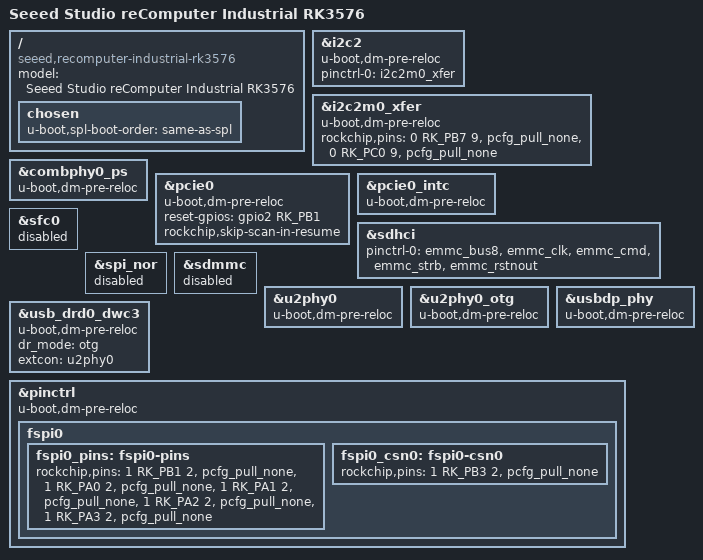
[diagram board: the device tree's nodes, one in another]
// SPDX-License-Identifier: (GPL-2.0+ OR MIT)
/*
 * Copyright (c) 2026 Seeed Studio
 *
 * U-Boot DTS for reComputer Industrial RK3576, eMMC SKU (no TF slot, no SPI
 * flash). Structure follows the hardware-validated devkit DTS (eMMC/fspi0
 * ball-sharing fix); board differences mirror the kernel industrial DTS.
 */

/dts-v1/;
#include "rk3576.dtsi"
#include "rk3576-u-boot.dtsi"

/ {
	model = "Seeed Studio reComputer Industrial RK3576";
	compatible = "seeed,recomputer-industrial-rk3576", "rockchip,rk3576";

	chosen {
		/*
		 * eMMC-only SKU: override the rk3576-u-boot.dtsi default
		 * (sdmmc/spi first). No TF slot, no SPI flash — go straight
		 * to on-board eMMC; "same-as-spl" (= eMMC) as fallback.
		 */
		u-boot,spl-boot-order = &sdhci, "same-as-spl";
	};
};

/*
 * SoM I2C2_M0: EEPROM FT24C32A @0x50 + RTC PCF85063 @0x51.
 * The boot script reads the EEPROM for board-ID DTB selection; the
 * misc.c patch (0011) reads per-port MACs from it (cpuid fallback).
 */
&i2c2 {
	u-boot,dm-pre-reloc;
	status = "okay";
	pinctrl-names = "default";
	pinctrl-0 = <&i2c2m0_xfer>;
};

&i2c2m0_xfer {
	u-boot,dm-pre-reloc;
	rockchip,pins =
		<0 RK_PB7 9 &pcfg_pull_none>,
		<0 RK_PC0 9 &pcfg_pull_none>;
};

/* M.2 Key-M NVMe on PCIE0, PERST GPIO2_B1, 3V3 always-on */
&combphy0_ps {
	u-boot,dm-pre-reloc;
	status = "okay";
};

&pcie0 {
	u-boot,dm-pre-reloc;
	reset-gpios = <&gpio2 RK_PB1 GPIO_ACTIVE_HIGH>;
	rockchip,skip-scan-in-resume;
	status = "okay";
};

&pcie0_intc {
	u-boot,dm-pre-reloc;
};

&sdhci {
	/*
	 * eMMC controller; bus-width/non-removable come from rk3576-u-boot.dtsi.
	 * RK3576 muxes func1=emmc / func2=fspi0 on the same balls
	 * (gpio1 A0-A7, B0-B2). Any fspi0 pinctrl steals the eMMC lines, so
	 * this no-SPI-flash board keeps sfc0/fspi0 disabled and muxes the
	 * pins to emmc explicitly here (same fix as the devkit).
	 */
	status = "okay";
	pinctrl-names = "default";
	pinctrl-0 = <&emmc_bus8 &emmc_clk &emmc_cmd &emmc_strb &emmc_rstnout>;
};

&sfc0 {
	/* eMMC SKU has no SPI flash; do not touch the shared fspi0/emmc balls. */
	status = "disabled";
};

&spi_nor {
	/* No SPI flash populated; probing it would grab the shared fspi0 pins. */
	status = "disabled";
};

&sdmmc {
	/* No TF slot on the industrial carrier. */
	status = "disabled";
};

/* Type-C0 OTG (AW35615 CC): rockusb / download mode */
&u2phy0 {
	u-boot,dm-pre-reloc;
	status = "okay";
};

&u2phy0_otg {
	u-boot,dm-pre-reloc;
	status = "okay";
};

&usbdp_phy {
	u-boot,dm-pre-reloc;
	status = "okay";
};

&usb_drd0_dwc3 {
	u-boot,dm-pre-reloc;
	dr_mode = "otg";
	extcon = <&u2phy0>;
	status = "okay";
};

&pinctrl {
	u-boot,dm-pre-reloc;
	u-boot,dm-spl;
	status = "okay";

	/delete-node/ fspi0;
	fspi0 {
		u-boot,dm-spl;
		fspi0_pins: fspi0-pins {
			u-boot,dm-spl;
			rockchip,pins =
				/* fspi0_clk */
				<1 RK_PB1 2 &pcfg_pull_none>,
				/* fspi0_d0 */
				<1 RK_PA0 2 &pcfg_pull_none>,
				/* fspi0_d1 */
				<1 RK_PA1 2 &pcfg_pull_none>,
				/* fspi0_d2 */
				<1 RK_PA2 2 &pcfg_pull_none>,
				/* fspi0_d3 */
				<1 RK_PA3 2 &pcfg_pull_none>;
		};

		fspi0_csn0: fspi0-csn0 {
			u-boot,dm-spl;
			rockchip,pins =
				/* fspi0_csn0 */
				<1 RK_PB3 2 &pcfg_pull_none>;
		};
	};
};
